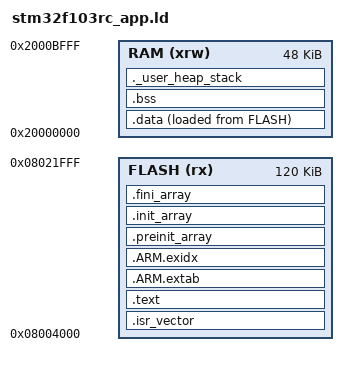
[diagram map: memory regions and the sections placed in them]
/* APP @ 0x08004000：与 bootloader 预留 16KB（0x4000）一致；STM32F103RC 共 256KB Flash */
ENTRY(Reset_Handler)

_estack = ORIGIN(RAM) + LENGTH(RAM);
_Min_Heap_Size = 0x0;
/*
 * 大缓冲已改为 .bss 静态区；栈仅保留调用深度即可。
 * RCT6 共 48KB RAM；与 standalone 一致，避免 .bss 与栈保留之和溢出。
 */
_Min_Stack_Size = 0xF00;

MEMORY
{
    FLASH (rx)  : ORIGIN = 0x08004000, LENGTH = 120K
    RAM   (xrw) : ORIGIN = 0x20000000, LENGTH = 48K
}

SECTIONS
{
    .isr_vector :
    {
        . = ALIGN(4);
        KEEP(*(.isr_vector))
        . = ALIGN(4);
    } > FLASH

    .text :
    {
        . = ALIGN(4);
        *(.text*)
        *(.rodata*)
        *(.glue_7)
        *(.glue_7t)
        *(.eh_frame)
        KEEP(*(.init))
        KEEP(*(.fini))
        . = ALIGN(4);
        _etext = .;
    } > FLASH

    .ARM.extab :
    {
        *(.ARM.extab* .gnu.linkonce.armextab.*)
    } > FLASH

    .ARM.exidx :
    {
        __exidx_start = .;
        *(.ARM.exidx*)
        __exidx_end = .;
    } > FLASH

    .preinit_array :
    {
        PROVIDE_HIDDEN (__preinit_array_start = .);
        KEEP (*(.preinit_array*))
        PROVIDE_HIDDEN (__preinit_array_end = .);
    } > FLASH

    .init_array :
    {
        PROVIDE_HIDDEN (__init_array_start = .);
        KEEP (*(SORT(.init_array.*)))
        KEEP (*(.init_array*))
        PROVIDE_HIDDEN (__init_array_end = .);
    } > FLASH

    .fini_array :
    {
        PROVIDE_HIDDEN (__fini_array_start = .);
        KEEP (*(SORT(.fini_array.*)))
        KEEP (*(.fini_array*))
        PROVIDE_HIDDEN (__fini_array_end = .);
    } > FLASH

    _sidata = LOADADDR(.data);
    .data :
    {
        . = ALIGN(4);
        _sdata = .;
        *(.data*)
        . = ALIGN(4);
        _edata = .;
    } > RAM AT > FLASH

    .bss (NOLOAD) :
    {
        . = ALIGN(4);
        _sbss = .;
        *(.bss*)
        *(COMMON)
        . = ALIGN(4);
        _ebss = .;
    } > RAM

    ._user_heap_stack (NOLOAD) :
    {
        . = ALIGN(8);
        PROVIDE(end = .);
        PROVIDE(_end = .);
        . = . + _Min_Heap_Size;
        . = . + _Min_Stack_Size;
        . = ALIGN(8);
    } > RAM

    /DISCARD/ :
    {
        *(.note*)
        *(.comment*)
    }
}
